# cslr_ectl register map
Vendor: Texas Instruments
Peripheral module from a debugger description file (folder TCI6484_C6457).
Registers are 32-bit, access not given, reset 0x0 unless marked. A register's access mark holds for its fields unless they carry their own. Offsets are as the file gives them; lines under a group give offsets from that group; [hi:lo] are bit positions; {n}, {i} and the like mark numbered series; 'fields as' and 'values as' point back to an identical list; <NAME> marks a mode.

## ECTL — Ethernet Control Module
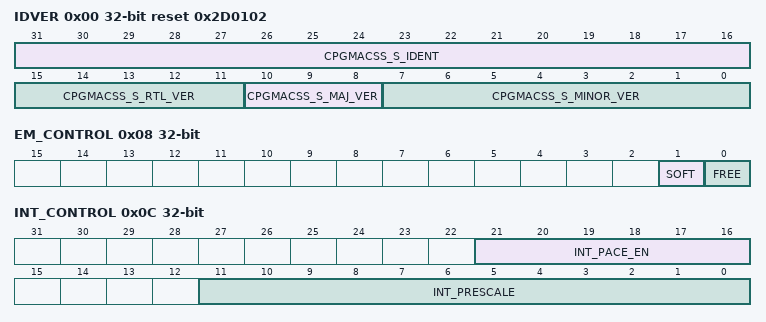
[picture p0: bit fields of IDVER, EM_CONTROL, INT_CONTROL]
0x00 IDVER ro reset 0x2D0102 — Identification and Version register
  [31:16] CPGMACSS_S_IDENT — CPGMACSS_S Identification value
  [15:11] CPGMACSS_S_RTL_VER — CPGMACSS_S RTL Version value
  [10:8] CPGMACSS_S_MAJ_VER — CPGMACSS_S Major Version Value
  [7:0] CPGMACSS_S_MINOR_VER — CPGMACSS_S Minor Version Value
0x04 SOFT_RESET — Software Reset Register
  [0] SOFT_RESET rw — Software reset  Writing a one to this bit causes the CPGMACSS_S logic to be reset (INT, REGS, CPPI). Software reset occurs on the clock following the register bit write.
0x08 EM_CONTROL — Emulation Control Register
  [1] SOFT rw — Emulation Soft Bit
  [0] FREE rw — Emulation Free Bit
0x0C INT_CONTROL — Interrupt Control Register
  [21:16] INT_PACE_EN rw — Interrupt Pacing Enable Bus
    0=ENABLE_RX (Enables Rx_Pulse Pacing); 1=ENABLE_TX (Enables Tx_Pulse Pacing)
  [11:0] INT_PRESCALE rw — Interrupt counter prescaler. The number of CPUCLK/6 periods in 4 ms.
0x10 RX_THRESH_EN — Receive Threshold Interrupt Enable Register
  [7:0] RX_THRESH_EN rw — Receive Threshold Enable - Each bit in this register corresponds to the bit in the receive threshold interrupt that is enabled to generate an interrupt on RX_THRESH_PULSE
0x14 RX_EN — Receive Interrupt Enable Register
  [7:0] RX_EN rw — Receive Enable - Each bit in this register corresponds to the bit in the rx interrupt that is enabled to generate an interrupt on RX_PULSE.
0x18 TX_EN — Transmit Interrupt Enable Register
  [7:0] TX_EN rw — Transmit Enable - Each bit in this register corresponds to the bit in the tx interrupt that is enabled to generate an interrupt on TX_PULSE.
0x1C MISC_EN — Misc Interrupt Enable Register
  [3:0] MISC_EN ro — Misc Enable - Each bit in this register corresponds to the miscellaneous interrupt (stat_pend, host_pend, mdio_linkint, mdio_userint) that is enabled to generate an interrupt on Misc_PULSE.
0x40 RX_THRESH_STAT — Receive Threshold Masked Interrupt Status Register
  [7:0] RX_THRESH_STAT rw — Receive Threshold Masked Interrupt Status - Each bit in this read only register corresponds to the bit in the receive threshold interrupt that is enabled and generating an interrupt on RX_THRESH_PULSE.
0x44 RX_STAT — Receive Interrupt Masked Interrupt Status Register
  [7:0] RX_STAT ro — Receive Masked Interrupt Status - Each bit in this read only register corresponds to the bit in the Rx interrupt that is enabled and generating an interrupt on RX_PULSE.
0x48 TX_STAT — Transmit Interrupt Masked Interrupt Status Register
  [7:0] TX_STAT ro — Transmit Masked Interrupt Status - Each bit in this read only register corresponds to the bit in the Tx interrupt that is enabled and generating an interrupt on TX_PULSE .
0x4C MISC_STAT — Misc Interrupt Masked Interrupt Status Register
  [3:0] MISC_STAT ro — Misc Masked Interrupt Status - Each bit in this register corresponds to the miscellaneous interrupt (stat_pend, host_pend, mdio_linkint, mdio_userint) that is enabled and generating an interrupt on MISC_PULSE .
0x70 RX_IMAX — Receive Interrupts Per Millisecond
  [5:0] RX_IMAX rw — Receive Interrupts per Millisecond - The maximum number of interrupts per millisecond generated on RX_PULSE if pacing is enabled for this interrupt.
0x74 TX_IMAX — Transmit Interrupts Per Millisecond
  [5:0] TX_IMAX rw — Transmit Interrupts per Millisecond - The maximum number of interrupts per millisecond generated on TX_PULSE if pacing is enabled for this interrupt.
